# WLR089U0 register map
Vendor: Microchip
Registers are 32-bit, read-write, reset 0x0 unless marked. A register's access mark holds for its fields unless they carry their own. Addresses are absolute, and some are shared; only a register's first bit layout is shown; [hi:lo] are bit positions; {n}, {i} and the like mark numbered series; 'fields as' and 'values as' point back to an identical list.

## MTB
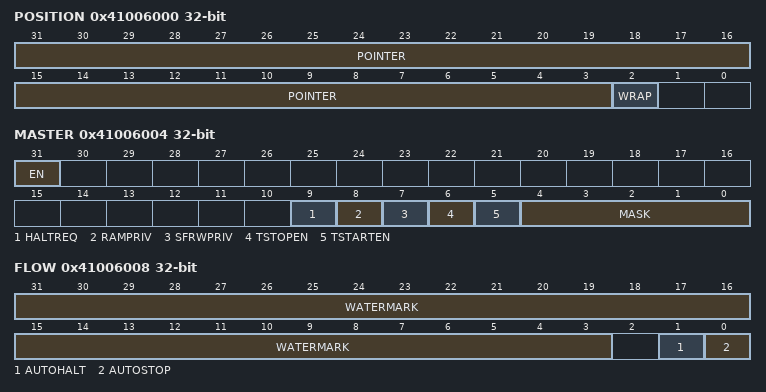
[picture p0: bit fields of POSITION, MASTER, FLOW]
0x41006000 POSITION reset not defined
  [31:3] POINTER — Trace Packet Location Pointer
  [2] WRAP — Pointer Value Wraps
0x41006004 MASTER
  [31] EN — Main Trace Enable
  [9] HALTREQ — Halt Request
  [8] RAMPRIV — SRAM Privilege
  [7] SFRWPRIV — Special Function Register Write Privilege
  [6] TSTOPEN — Trace Stop Input Enable
  [5] TSTARTEN — Trace Start Input Enable
  [4:0] MASK — Maximum Value of the Trace Buffer in SRAM
0x41006008 FLOW
  [31:3] WATERMARK — Watermark value
  [1] AUTOHALT — Auto Halt Request
  [0] AUTOSTOP — Auto Stop Tracing
0x4100600C BASE ro reset not defined
0x41006F00 ITCTRL reset not defined
0x41006FA0 CLAIMSET reset not defined
0x41006FA4 CLAIMCLR reset not defined
0x41006FB0 LOCKACCESS reset not defined
0x41006FB4 LOCKSTATUS ro reset not defined
0x41006FB8 AUTHSTATUS ro reset not defined
0x41006FBC DEVARCH ro reset not defined
0x41006FC8 DEVID ro reset not defined
0x41006FCC DEVTYPE ro reset not defined
{0x41006FC0+4i} PID{i} ro reset not defined (i=4..7)
{0x41006FE0+4i} PID{i} ro reset not defined (i=0..3)
{0x41006FF0+4i} CID{i} ro reset not defined (i=0..3)

## TC0
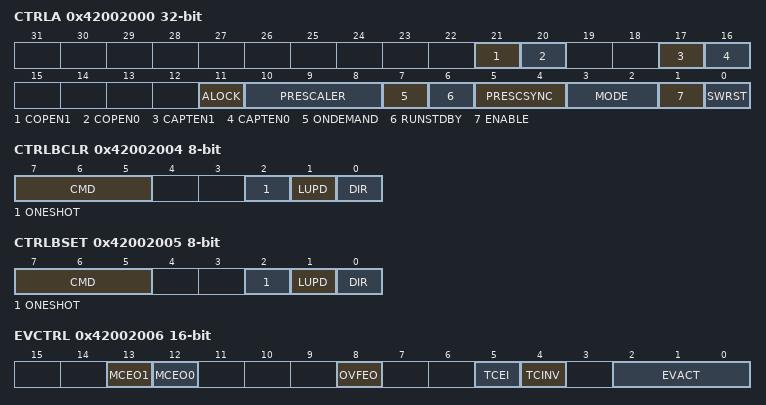
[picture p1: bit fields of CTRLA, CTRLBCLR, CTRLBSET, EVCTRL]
0x42002000 CTRLA
  [21] COPEN1 — Capture On Pin 1 Enable
  [20] COPEN0 — Capture On Pin 0 Enable
  [17] CAPTEN1 — Capture Channel 1 Enable
  [16] CAPTEN0 — Capture Channel 0 Enable
  [11] ALOCK — Auto Lock
  [10:8] PRESCALER
    0=DIV1 (Prescaler: GCLK_TC); 1=DIV2 (Prescaler: GCLK_TC/2); 2=DIV4 (Prescaler: GCLK_TC/4); 3=DIV8 (Prescaler: GCLK_TC/8); 4=DIV16 (Prescaler: GCLK_TC/16); 5=DIV64 (Prescaler: GCLK_TC/64); 6=DIV256 (Prescaler: GCLK_TC/256); 7=DIV1024 (Prescaler: GCLK_TC/1024)
  [7] ONDEMAND — Clock On Demand
  [6] RUNSTDBY — Run during Standby
  [5:4] PRESCSYNC — Prescaler and Counter Synchronization
    0=GCLK (Reload or reset the counter on next generic clock); 1=PRESC (Reload or reset the counter on next prescaler clock); 2=RESYNC (Reload or reset the counter on next generic clock and reset the prescaler counter)
  [3:2] MODE — Timer Counter Mode
    0=COUNT16 (Counter in 16-bit mode); 1=COUNT8 (Counter in 8-bit mode); 2=COUNT32 (Counter in 32-bit mode)
  [1] ENABLE
  [0] SWRST — Software Reset
0x42002004 CTRLBCLR 8-bit
  [7:5] CMD — Command
    0=NONE (No action); 1=RETRIGGER (Force a start, restart or retrigger); 2=STOP (Force a stop); 3=UPDATE (Force update of double-buffered register); 4=READSYNC (Force a read synchronization of COUNT); 5=DMAOS (One-shot DMA trigger)
  [2] ONESHOT — One-Shot on Counter
  [1] LUPD — Lock Update
  [0] DIR — Counter Direction
0x42002005 CTRLBSET 8-bit
  fields as CTRLBCLR
0x42002006 EVCTRL 16-bit
  [13] MCEO1 — MC Event Output Enable 1
  [12] MCEO0 — MC Event Output Enable 0
  [8] OVFEO — Event Output Enable
  [5] TCEI — TC Event Enable
  [4] TCINV — TC Event Input Polarity
  [2:0] EVACT — Event Action
    0=OFF (Event action disabled); 1=RETRIGGER (Start, restart or retrigger TC on event); 2=COUNT (Count on event); 3=START (Start TC on event); 4=STAMP (Time stamp capture); 5=PPW (Period captured in CC0, pulse width in CC1); 6=PWP (Period captured in CC1, pulse width in CC0); 7=PW (Pulse width capture)
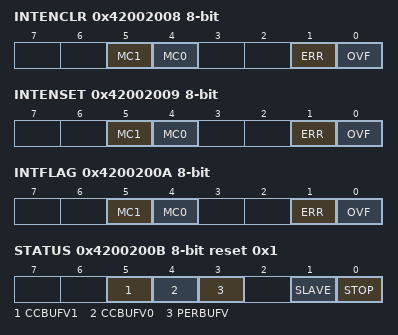
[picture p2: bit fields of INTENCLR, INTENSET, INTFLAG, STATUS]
0x42002008 INTENCLR 8-bit
  [5] MC1 — MC Interrupt Disable 1
  [4] MC0 — MC Interrupt Disable 0
  [1] ERR — ERR Interrupt Disable
  [0] OVF — OVF Interrupt Disable
0x42002009 INTENSET 8-bit
  [5] MC1 — MC Interrupt Enable 1
  [4] MC0 — MC Interrupt Enable 0
  [1] ERR — ERR Interrupt Enable
  [0] OVF — OVF Interrupt Enable
0x4200200A INTFLAG 8-bit
  [5] MC1 — MC Interrupt Flag 1
  [4] MC0 — MC Interrupt Flag 0
  [1] ERR — ERR Interrupt Flag
  [0] OVF — OVF Interrupt Flag
0x4200200B STATUS 8-bit reset 0x1
  [5] CCBUFV1 — Compare channel buffer 1 valid
  [4] CCBUFV0 — Compare channel buffer 0 valid
  [3] PERBUFV — Synchronization Busy Status
  [1] SLAVE — Slave Status Flag
  [0] STOP — Stop Status Flag
0x4200200C WAVE 8-bit
  [1:0] WAVEGEN — Waveform Generation Mode
    0=NFRQ (Normal frequency); 1=MFRQ (Match frequency); 2=NPWM (Normal PWM); 3=MPWM (Match PWM)
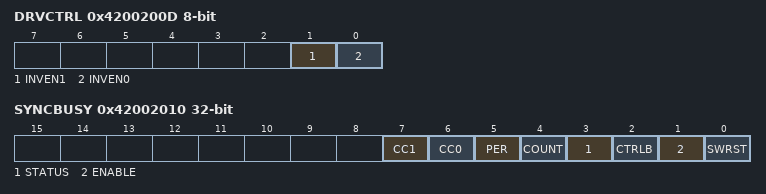
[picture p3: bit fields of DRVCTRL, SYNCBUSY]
0x4200200D DRVCTRL 8-bit
  [1] INVEN1 — Output Waveform Invert Enable 1
  [0] INVEN0 — Output Waveform Invert Enable 0
0x4200200F DBGCTRL 8-bit
  [0] DBGRUN — Run During Debug
0x42002010 SYNCBUSY ro
  [7] CC1 — Compare Channel 1
  [6] CC0 — Compare Channel 0
  [5] PER — Period
  [4] COUNT — Counter
  [3] STATUS
  [2] CTRLB
  [1] ENABLE
  [0] SWRST
